# STM32U083 register map
File version: 1.0
CPU: CM0+ r0p1, little endian, MPU, no FPU, 4 interrupt priority bits
Registers are 32-bit, read-write, reset 0x0 unless marked. A register's access mark holds for its fields unless they carry their own. Offsets are from the block's base; [hi:lo] are bit positions.

## DBGMCU — DBGMCU register block
Base 0x40015800
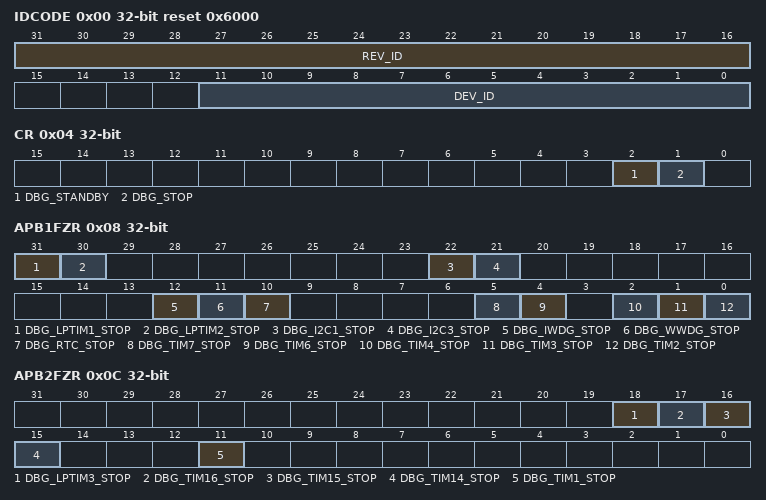
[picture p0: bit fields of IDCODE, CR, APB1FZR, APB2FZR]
0x00 IDCODE ro reset 0x6000 (reset mask 0xF000) — DBGMCU device ID code register
  [31:16] REV_ID — Revision identifier This field indicates the revision of the device.
  [11:0] DEV_ID — Device identifier This field indicates the device ID.
0x04 CR — DBGMCU configuration register
  [2] DBG_STANDBY — Debug Standby and Shutdown modes Debug options in Standby or Shutdown mode.
  [1] DBG_STOP — Debug Stop mode Debug options in Stop mode.
0x08 APB1FZR — DBGMCU APB1 freeze register
  [31] DBG_LPTIM1_STOP — LPTIM1 stop in debug
  [30] DBG_LPTIM2_STOP — LPTIM2 stop in debug
  [22] DBG_I2C1_STOP — I2C1 SMBUS timeout stop in debug
  [21] DBG_I2C3_STOP — I2C3 SMBUS timeout stop in debug
  [12] DBG_IWDG_STOP — IWDG stop in debug
  [11] DBG_WWDG_STOP — WWDG stop in debug
  [10] DBG_RTC_STOP — RTC stop in debug
  [5] DBG_TIM7_STOP — TIM7 stop in debug
  [4] DBG_TIM6_STOP — TIM6 stop in debug
  [2] DBG_TIM4_STOP — TIM4 stop in debug
  [1] DBG_TIM3_STOP — TIM3 stop in debug
  [0] DBG_TIM2_STOP — TIM2 stop in debug
0x0C APB2FZR — DBG APB2 freeze register
  [18] DBG_LPTIM3_STOP — LPTIM3 stop in debug
  [17] DBG_TIM16_STOP — TIM16 stop in debug
  [16] DBG_TIM15_STOP — TIM15 stop in debug
  [15] DBG_TIM14_STOP — TIM14 stop in debug
  [11] DBG_TIM1_STOP — TIM1 stop in debug
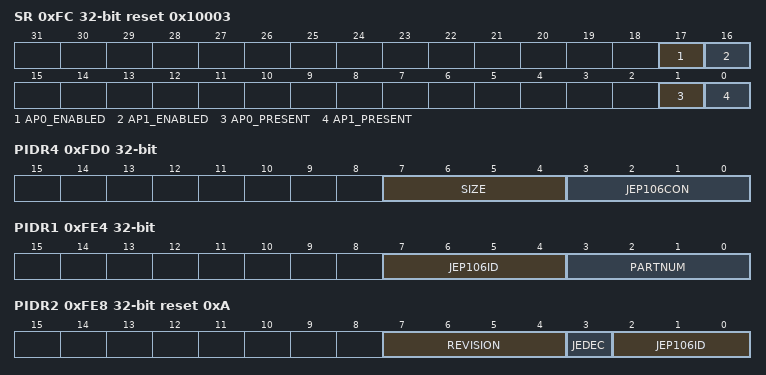
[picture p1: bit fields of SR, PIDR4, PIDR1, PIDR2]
0xFC SR ro reset 0x10003 — DBGMCU status register
  [17] AP0_ENABLED — Identifies whether access port AP0 is open (can be accessed via the debug port) or locked (debug access to the AP is blocked)
  [16] AP1_ENABLED — Identifies whether access port AP0 is open (can be accessed via the debug port) or locked (debug access to the AP is blocked)
  [1] AP0_PRESENT — Identifies whether access port AP0 is present in device
  [0] AP1_PRESENT — Identifies whether access port AP1 is present in device
0x100 DBG_AUTH_HOST reset not defined — DBGMCU debug authentication mailbox host register
  [31:0] MESSAGE — Debug host to device mailbox message. During debug authentication the debug host communicates with the device via this register.
0x104 DBG_AUTH_DEVICE ro reset not defined — DBGMCU debug authentication mailbox device register
  [31:0] MESSAGE — Device to debug host mailbox message. During debug authentication the device communicates with the debug host via this register.
0xFD0 PIDR4 ro — DBGMCU CoreSight peripheral identity register 4
  [7:4] SIZE — register file size
  [3:0] JEP106CON — JEP106 continuation code
0xFE0 PIDR0 ro — DBGMCU CoreSight peripheral identity register 0
  [7:0] PARTNUM — part number bits [7:0]
0xFE4 PIDR1 ro — DBGMCU CoreSight peripheral identity register 1
  [7:4] JEP106ID — JEP106 identity code bits [3:0]
  [3:0] PARTNUM — part number bits [11:8]
0xFE8 PIDR2 ro reset 0xA — DBGMCU CoreSight peripheral identity register 2
  [7:4] REVISION — component revision number
  [3] JEDEC — JEDEC assigned value
  [2:0] JEP106ID — JEP106 identity code bits [6:4]
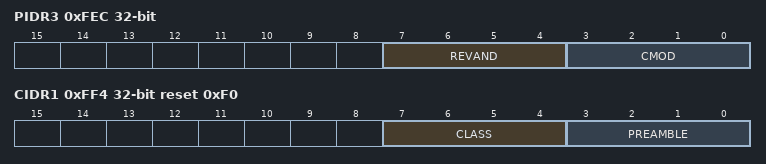
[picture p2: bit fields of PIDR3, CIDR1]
0xFEC PIDR3 ro — DBGMCU CoreSight peripheral identity register 3
  [7:4] REVAND — metal fix version
  [3:0] CMOD — customer modified
0xFF0 CIDR0 ro reset 0xD — DBGMCU CoreSight component identity register 0
  [7:0] PREAMBLE — component identification bits [7:0]
0xFF4 CIDR1 ro reset 0xF0 — DBGMCU CoreSight component identity register 1
  [7:4] CLASS — component identification bits [15:12] - component class
  [3:0] PREAMBLE — component identification bits [11:8]
0xFF8 CIDR2 ro reset 0x5 — DBGMCU CoreSight component identity register 2
  [7:0] PREAMBLE — component identification bits [23:16]
0xFFC CIDR3 ro reset 0xB1 — DBGMCU CoreSight component identity register 3
  [7:0] PREAMBLE — component identification bits [31:24]
